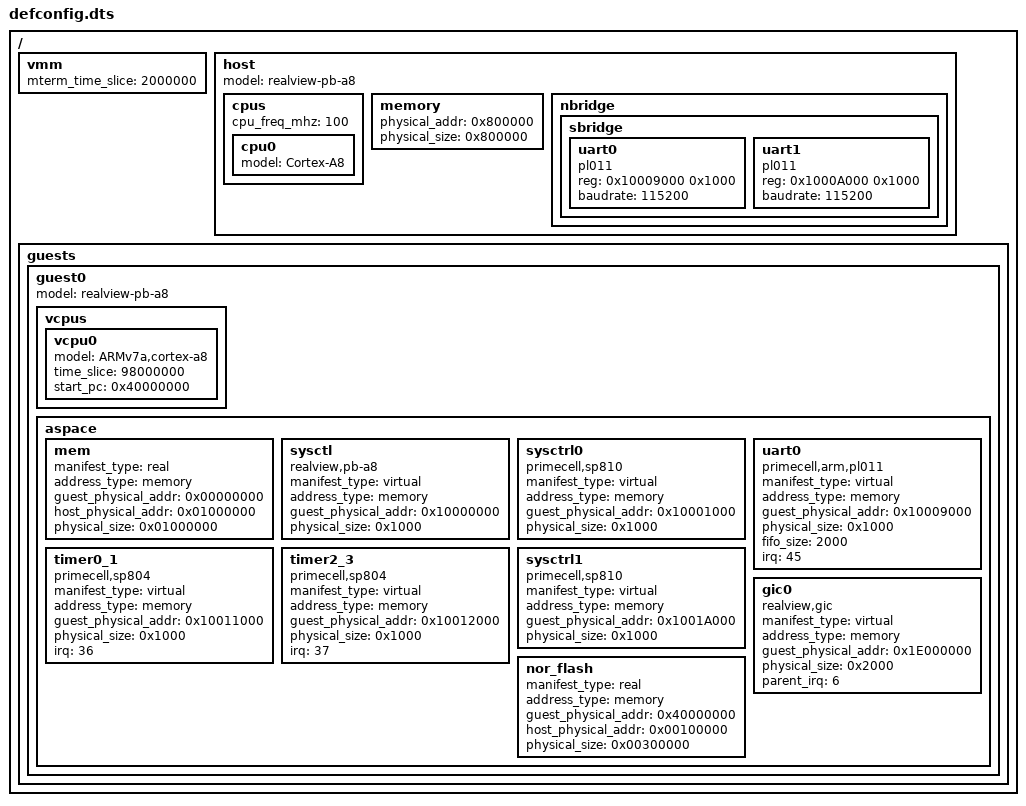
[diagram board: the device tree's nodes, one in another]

/dts-v1/;

/ {
	vmm {
		#address-cells = <1>;
		#size-cells = <0>;
		mterm_time_slice = <2000000>;
	};

	host {
		#address-cells = <2>;
		#size-cells = <1>;
		model = "realview-pb-a8";
		device_type = "host";
		
		cpus {
			#address-cells = <1>;
			#size-cells = <0>;
			cpu_freq_mhz = <100>;

			cpu0 {
				device_type = "cpu";
				model = "Cortex-A8";
			};
		};

		memory {
			#address-cells = <1>;
			#size-cells = <0>;
			physical_addr = <0x800000>;
			physical_size = <0x800000>;
		};

		nbridge {
			#address-cells = <1>;
			#size-cells = <0>;
		
			sbridge {
				#address-cells = <1>;
				#size-cells = <0>;
		
				uart0 {
			      		device_type = "serial";
			      		compatible = "pl011";
			      		reg = <0x10009000 0x1000>;
			      		baudrate = <115200>;
				};

				uart1 {
			      		device_type = "serial";
			      		compatible = "pl011";
			      		reg = <0x1000A000 0x1000>;
			      		baudrate = <115200>;
				};
			};
		};
	};

	guests {
		#address-cells = <1>;
		#size-cells = <0>;

		guest0 {
			#address-cells = <1>;
			#size-cells = <0>;
			model = "realview-pb-a8";
			device_type = "guest";

			vcpus {
				#address-cells = <1>;
				#size-cells = <0>;

				vcpu0 {
					device_type = "vcpu";
					model = "ARMv7a,cortex-a8";
					time_slice = <98000000>;
					start_pc = <0x40000000>;
				};
			};
			
			aspace {
				#address-cells = <1>;
				#size-cells = <0>;

				mem {
					manifest_type = "real";
					address_type = "memory";
					guest_physical_addr = <0x00000000>;
					host_physical_addr = <0x01000000>;
					physical_size = <0x01000000>; /* 16 MB */
					device_type = "ram";
				};

				sysctl {
					manifest_type = "virtual";
					address_type = "memory";
					guest_physical_addr = <0x10000000>;
					physical_size = <0x1000>;
					device_type = "sys";
					compatible = "realview,pb-a8";
				};

				sysctrl0 {
					manifest_type = "virtual";
					address_type = "memory";
					guest_physical_addr = <0x10001000>;
					physical_size = <0x1000>;
					device_type = "sys";
					compatible = "primecell,sp810";
				};

				uart0 {
					manifest_type = "virtual";
					address_type = "memory";
					guest_physical_addr = <0x10009000>;
					physical_size = <0x1000>;
					device_type = "serial";
					compatible = "primecell,arm,pl011";
					fifo_size = <2000>;
					irq = <45>;
				};

				timer0_1 {
					manifest_type = "virtual";
					address_type = "memory";
					guest_physical_addr = <0x10011000>;
					physical_size = <0x1000>;
					device_type = "timer";
					compatible = "primecell,sp804";
					irq = <36>;
				};

				timer2_3 {
					manifest_type = "virtual";
					address_type = "memory";
					guest_physical_addr = <0x10012000>;
					physical_size = <0x1000>;
					device_type = "timer";
					compatible = "primecell,sp804";
					irq = <37>;
				};

				sysctrl1 {
					manifest_type = "virtual";
					address_type = "memory";
					guest_physical_addr = <0x1001A000>;
					physical_size = <0x1000>;
					device_type = "sys";
					compatible = "primecell,sp810";
				};

				gic0 {
					manifest_type = "virtual";
					address_type = "memory";
					guest_physical_addr = <0x1E000000>;
					physical_size = <0x2000>;
					device_type = "pic";
					compatible = "realview,gic";
					parent_irq = <6>;
				};

				nor_flash {
					manifest_type = "real";
					address_type = "memory";
					guest_physical_addr = <0x40000000>;
					host_physical_addr = <0x00100000>;
					physical_size = <0x00300000>; /* 3 MB */
					device_type = "rom";
				};
			};
		};

	};
};
